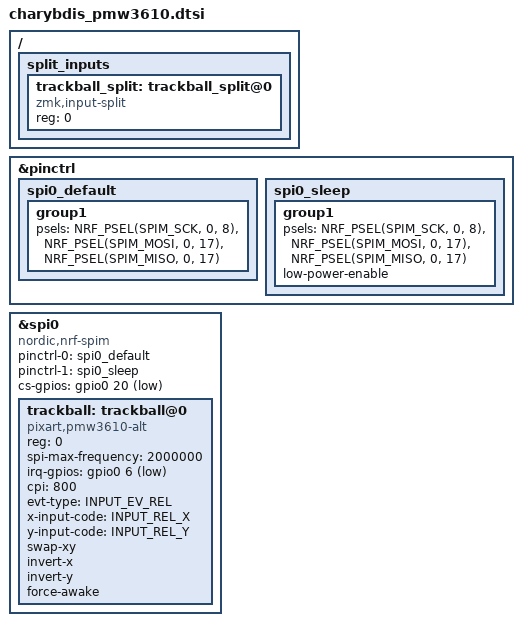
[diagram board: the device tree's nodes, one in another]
/*
 * Copyright (c) 2026 The ZMK Contributors
 * SPDX-License-Identifier: MIT
 *
 * PixArt PMW3610 Optical Trackball Sensor (Right Half SPI0)
 * Reverse-engineered 1:1 from factory charybdis_right-nice_nano_v2-zmk.uf2:
 *   SCK  = P0.08 (&pro_micro 0 / D0)
 *   SDIO = P0.17 (&pro_micro 2 / D2, half-duplex MOSI+MISO)
 *   CS   = P0.20 (&pro_micro 3 / D3, active-low)
 *   IRQ  = P0.06 (&pro_micro 1 / D1, active-low + pull-up)
 *   Orientation in factory firmware: X_out = -raw_y, Y_out = -raw_x => swap-xy + invert-x + invert-y
 */

#include <zephyr/dt-bindings/input/input-event-codes.h>

&pinctrl {
    spi0_default: spi0_default {
        group1 {
            psels = <NRF_PSEL(SPIM_SCK, 0, 8)>,
                    <NRF_PSEL(SPIM_MOSI, 0, 17)>,
                    <NRF_PSEL(SPIM_MISO, 0, 17)>;
        };
    };

    spi0_sleep: spi0_sleep {
        group1 {
            psels = <NRF_PSEL(SPIM_SCK, 0, 8)>,
                    <NRF_PSEL(SPIM_MOSI, 0, 17)>,
                    <NRF_PSEL(SPIM_MISO, 0, 17)>;
            low-power-enable;
        };
    };
};

&spi0 {
    status = "okay";
    compatible = "nordic,nrf-spim";
    pinctrl-0 = <&spi0_default>;
    pinctrl-1 = <&spi0_sleep>;
    pinctrl-names = "default", "sleep";
    cs-gpios = <&gpio0 20 GPIO_ACTIVE_LOW>;

    trackball: trackball@0 {
        status = "okay";
        compatible = "pixart,pmw3610-alt";
        reg = <0>;
        spi-max-frequency = <2000000>;
        irq-gpios = <&gpio0 6 (GPIO_ACTIVE_LOW | GPIO_PULL_UP)>;

        /*
         * Чувствительность сенсора (шаг 200, диапазон 200..3200).
         * В заводской прошивке стояло 1200; 800 даёт оптимальный баланс точности и плавности.
         */
        cpi = <800>;

        evt-type = <INPUT_EV_REL>;
        x-input-code = <INPUT_REL_X>;
        y-input-code = <INPUT_REL_Y>;

        /* Ориентация сенсора данной платы (подтверждено дизассемблированием 0x0005ACC6..0x0005AD8C) */
        swap-xy;
        invert-x;
        invert-y;

        /* Удерживает сенсор активным в режиме ACTIVE и переводит в REST при IDLE/SLEEP */
        force-awake;
    };
};

/ {
    /* Канал пересылки движений трекбола по BLE для режима с внешним USB-донглом */
    split_inputs {
        #address-cells = <1>;
        #size-cells = <0>;

        trackball_split: trackball_split@0 {
            compatible = "zmk,input-split";
            reg = <0>;
        };
    };
};
